# soc_aon_secure register map
Vendor: Texas Instruments
Registers are 32-bit, access per field, reset 0x0 unless marked. A register's access mark holds for its fields unless they carry their own. Offsets are as the file gives them; [hi:lo] are bit positions; {n}, {i} and the like mark numbered series; 'fields as' and 'values as' point back to an identical list; <NAME> marks a mode.

## soc_aon_secure (part 2 of 3)
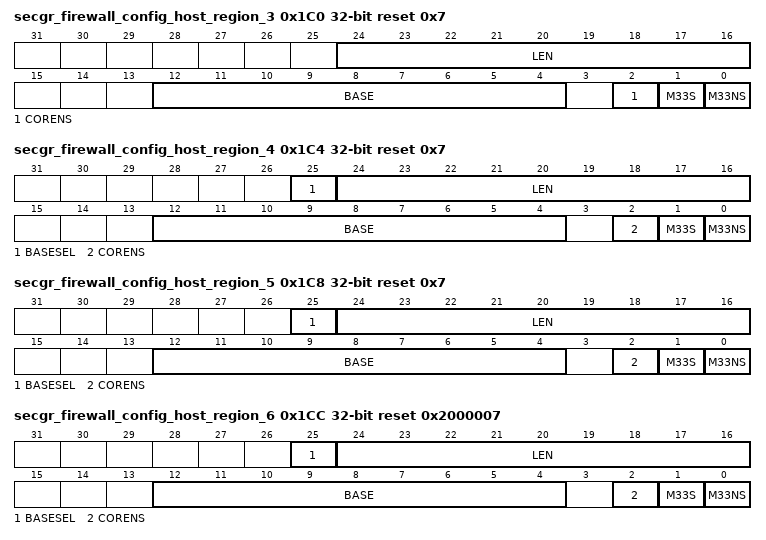
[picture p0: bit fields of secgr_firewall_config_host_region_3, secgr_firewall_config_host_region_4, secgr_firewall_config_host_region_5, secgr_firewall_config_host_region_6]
0x1C0 secgr_firewall_config_host_region_3 reset 0x7 — HOST MCU region 3 firewall access permission for 3 controller id : 0 - M33 Non Secured 1 - M33 Secured 2 - Core (Non Secure)
  [24:16] LEN rw — address base with 1K granularity : address base len for firewall is the offset from the region's base address indicated in the same region field describing the end of a firewall window that has a certain access rules (R/W Permission) for each controller-id HOST_MCU_REGION_0 address space: 0x20000000 - 0x2FFFFFFF HOST_MCU_REGION_0 base_len can range from: ##register base_len value## 0x0 - 0x7F for HOST_MCU_REGION_0 the base address for security firewalls is 0x20000000 ( HOST_MCU_REGION_0 ) max window size is 128Kb example: worker base address: 0x20000000 current address to access: 0x20001504 region_base_address: 0x4 region_base_address_len: 0x2 --> (region_base_address + region_base_address_len) --> 0x4+0x2 -->0x6 0x20001504 --> ((0x20001504 - 0x20000000) >> 10) -->0x4 0x4 <= 0x5 < 0x6 that address falls on the region window and therefor obeys to that region set of access rules
  [12:4] BASE rw — address base with 1K granularity : address base for firewall is the the offset start address from a worker base address describing the beginning of a firewall window that has a certain access rules (R/W Permission) for each controller-id HOST_MCU address space: 0x00000000 - 0x2FFFFFFF / 0x41900000 - 0x4190FFFF HOST_MCU_REGION_3 is assigned to TCM DATA RAM HOST_MCU_REGION_3 base address can range from: ##register base value## 0x0 - 0x1A0 ##absolute equivalent value## 0x280000000 - 0x280068000 for HOST_MCU_REGION_3 the base address for security firewalls is 0x280000000 ( M33 Data RAM ) max window size is 416Kb (depending on the MEMSS mode) example: worker base address: 0x280000000 current address to access: 0x28000504 region_base_address: 0x1 region_base_address_len: 0x1 0x28000504 --> ((0x28000504 - 0x280000000) >> 10) --> 0x1 0x1(base) <= 0x1(current) < 0x1(base)+0x1(len) that address falls on the region window and therefor obeys to that region set of access rules
  [2] CORENS rw — Controller Core Non Secured: '0' - access not allowed '1' - access allowed
  [1] M33S rw — Controller M33 Secured: '0' - access not allowed '1' - access allowed
  [0] M33NS rw — Controller M33 None Secured: '0' - access not allowed '1' - access allowed
0x1C4 secgr_firewall_config_host_region_4 reset 0x7 — access permission for 3 controller id : 0 - M33 Non Secured 1 - M33 Secured 2 - Core (Non Secure)
  [25] BASESEL rw — Base select for Reserved region defaulted to M33 TCM Data RAM (base_sel = 0): this select bit will assign this region to either TCM Data (base_sel = 0) ##register base value## 0x0 - 0x80 ##absolute equivalent value## 0x200000000 - 0x20001FFFF or Data RAM (base_sel = 1) ##register base value## 0x0 - 0x1A0 ##absolute equivalent value## 0x280000000 - 0x280067FFF for HOST_MCU_REGION_4 with base_sel = 0 the base address for security firewalls is 0x200000000 ( M33 TCM Data RAM ) max window size is 128Kb (depending on the MEMSS mode) for HOST_MCU_REGION_4 with base_sel = 1 the base address for security firewalls is 0x280000000 ( M33 Data RAM ) max window size is 416Kb (depending on the MEMSS mode) example: worker base address: 0x280000000 current address to access: 0x28000504 region_base_address: 0x1 region_base_address_len: 0x1 0x28000504 --> ((0x28000504 - 0x280000000) >> 10) --> 0x1 0x1(base) <= 0x1(current) < 0x1(base)+0x1(len) that address falls on the region window and therefor obeys to that region set of access rules
  [24:16] LEN rw — address base len for firewall is the offset from the region's base address indicated in the same region field describing the end of a firewall window that has a certain access rules (R/W Permission) for each controller-id HOST_MCU_REGION_4 address space: 0x20000000 - 0x2FFFFFFF HOST_MCU_REGION_4 base_len can range from: base_sel = 0 ##register base_len value## 0x0 - 0x7F base_sel = 0 --> HOST_MCU_REGION_4 the base address for security firewalls is 0x20000000 ( TCM M33 Data RAM ) max window size is 128Kb ################# base_sel = 1 ##register base_len value## 0x0 - 0x1A0 base_sel = 1 --> HOST_MCU_REGION_4 the base address for security firewalls is 0x28000000 (M33 Data RAM ) max window size is 416Kb ################# example: worker base address: 0x20000000 current address to access: 0x20001504 region_base_address: 0x4 region_base_address_len: 0x2 --> (region_base_address + region_base_address_len) --> 0x4+0x2 -->0x6 0x20001504 --> ((0x20001504 - 0x20000000) >> 10) -->0x4 0x4 <= 0x5 < 0x6 that address falls on the region window and therefor obeys to that region set of access rules
  [12:4] BASE rw — address base with 1K granularity : address base for firewall is the the offset start address from a worker base address describing the beginning of a firewall window that has a certain access rules (R/W Permission) for each controller-id HOST_MCU address space: 0x00000000 - 0x2FFFFFFF / 0x41900000 - 0x4190FFFF HOST_MCU_REGION_4 is assigned to TCM DATA RAM (base_sel = 0) or M33 Data Ram (base_sel = 1) HOST_MCU_REGION_4 base address can range from: (base_sel = 0) ##register base value## 0x0 - 0x80 ##absolute equivalent value## 0x200000000 - 0x20001FFFF for HOST_MCU_REGION_4 the base address for security firewalls is 0x200000000 ( TCM Data RAM ) max window size is 128Kb ################## (base_sel = 1) ##register base value## 0x0 - 0x1A0 ##absolute equivalent value## 0x280000000 - 0x280068000 for HOST_MCU_REGION_4 the base address for security firewalls is 0x280000000 ( M33 Data RAM ) max window size is 416Kb (depending on the MEMSS mode) example: worker base address: 0x280000000 current address to access: 0x28000504 region_base_address: 0x1 region_base_address_len: 0x1 0x28000504 --> ((0x28000504 - 0x280000000) >> 10) --> 0x1 0x1(base) <= 0x1(current) < 0x1(base)+0x1(len) that address falls on the region window and therefor obeys to that region set of access rules
  [2] CORENS rw — Controller Core Non Secured: '0' - access not allowed '1' - access allowed
  [1] M33S rw — Controller M33 Secured: '0' - access not allowed '1' - access allowed
  [0] M33NS rw — Controller M33 None Secured: '0' - access not allowed '1' - access allowed
0x1C8 secgr_firewall_config_host_region_5 reset 0x7 — HOST MCU region 5 firewall access permission for 3 controller id : 0 - M33 Non Secured 1 - M33 Secured 2 - Core (Non Secure)
  [25] BASESEL rw — Base select for Reserved region defaulted to M33 TCM Data RAM (base_sel = 0): this select bit will assign this region to either TCM Data (base_sel = 0) ##register base value## 0x0 - 0x80 ##absolute equivalent value## 0x200000000 - 0x20001FFFF or Data RAM (base_sel = 1) ##register base value## 0x0 - 0x1A0 ##absolute equivalent value## 0x280000000 - 0x280067FFF for HOST_MCU_REGION_5 with base_sel = 0 the base address for security firewalls is 0x200000000 ( M33 TCM Data RAM ) max window size is 128Kb (depending on the MEMSS mode) for HOST_MCU_REGION_5 with base_sel = 1 the base address for security firewalls is 0x280000000 ( M33 Data RAM ) max window size is 416Kb (depending on the MEMSS mode) example: worker base address: 0x280000000 current address to access: 0x28000504 region_base_address: 0x1 region_base_address_len: 0x1 0x28000504 --> ((0x28000504 - 0x280000000) >> 10) --> 0x1 0x1(base) <= 0x1(current) < 0x1(base)+0x1(len) that address falls on the region window and therefor obeys to that region set of access rules
  [24:16] LEN rw — address base len for firewall is the offset from the region's base address indicated in the same region field describing the end of a firewall window that has a certain access rules (R/W Permission) for each controller-id HOST_MCU_REGION_4 address space: 0x20000000 - 0x2FFFFFFF HOST_MCU_REGION_4 base_len can range from: base_sel = 0 ##register base_len value## 0x0 - 0x7F base_sel = 0 --> HOST_MCU_REGION_5 the base address for security firewalls is 0x20000000 ( TCM Data RAM ) max window size is 128Kb ################# base_sel = 1 ##register base_len value## 0x0 - 0x1A0 base_sel = 1 --> HOST_MCU_REGION_5 the base address for security firewalls is 0x28000000 ( M33 Data RAM ) max window size is 416Kb ################# example: worker base address: 0x20000000 current address to access: 0x20001504 region_base_address: 0x4 region_base_address_len: 0x2 --> (region_base_address + region_base_address_len) --> 0x4+0x2 -->0x6 0x20001504 --> ((0x20001504 - 0x20000000) >> 10) -->0x4 0x4 <= 0x5 < 0x6 that address falls on the region window and therefor obeys to that region set of access rules
  [12:4] BASE rw — address base with 1K granularity : address base for firewall is the the offset start address from a worker base address describing the beginning of a firewall window that has a certain access rules (R/W Permission) for each controller-id HOST_MCU address space: 0x00000000 - 0x2FFFFFFF / 0x41900000 - 0x4190FFFF HOST_MCU_REGION_5 is assigned to TCM DATA RAM (base_sel = 0) or M33 Data Ram (base_sel = 1) HOST_MCU_REGION_5 base address can range from: (base_sel = 0) ##register base value## 0x0 - 0x80 ##absolute equivalent value## 0x200000000 - 0x20001FFFF for HOST_MCU_REGION_5 the base address for security firewalls is 0x200000000 ( TCM Data RAM ) max window size is 128Kb ################## (base_sel = 1) ##register base value## 0x0 - 0x1A0 ##absolute equivalent value## 0x280000000 - 0x280068000 for HOST_MCU_REGION_5 the base address for security firewalls is 0x280000000 ( M33 Data RAM ) max window size is 416Kb (depending on the MEMSS mode) example: worker base address: 0x280000000 current address to access: 0x28000504 region_base_address: 0x1 region_base_address_len: 0x1 0x28000504 --> ((0x28000504 - 0x280000000) >> 10) --> 0x1 0x1(base) <= 0x1(current) < 0x1(base)+0x1(len) that address falls on the region window and therefor obeys to that region set of access rules
  [2] CORENS rw — Controller Core Non Secured: '0' - access not allowed '1' - access allowed
  [1] M33S rw — Controller M33 Secured: '0' - access not allowed '1' - access allowed
  [0] M33NS rw — Controller M33 None Secured: '0' - access not allowed '1' - access allowed
0x1CC secgr_firewall_config_host_region_6 reset 0x2000007 — HOST MCU region 6 firewall access permission for 3 controller id : 0 - M33 Non Secured 1 - M33 Secured 2 - Core (Non Secure)
  [25] BASESEL rw — Base select for Reserved region defaulted to M33 Data RAM (base_sel = 1): this select bit will assign this region to either TCM Data (base_sel = 0) ##register base value## 0x0 - 0x80 ##absolute equivalent value## 0x200000000 - 0x20001FFFF or Data RAM (base_sel = 1) ##register base value## 0x0 - 0x1A0 ##absolute equivalent value## 0x280000000 - 0x280067FFF for HOST_MCU_REGION_4 with base_sel = 0 the base address for security firewalls is 0x200000000 ( M33 TCM Data RAM ) max window size is 128Kb (depending on the MEMSS mode) for HOST_MCU_REGION_4 with base_sel = 1 the base address for security firewalls is 0x280000000 ( M33 Data RAM ) max window size is 416Kb (depending on the MEMSS mode) example: worker base address: 0x280000000 current address to access: 0x28000504 region_base_address: 0x1 region_base_address_len: 0x1 0x28000504 --> ((0x28000504 - 0x280000000) >> 10) --> 0x1 0x1(base) <= 0x1(current) < 0x1(base)+0x1(len) that address falls on the region window and therefor obeys to that region set of access rules
  [24:16] LEN rw — address base len for firewall is the offset from the region's base address indicated in the same region field describing the end of a firewall window that has a certain access rules (R/W Permission) for each controller-id HOST_MCU_REGION_6 address space: 0x20000000 - 0x2FFFFFFF HOST_MCU_REGION_6 base_len can range from: base_sel = 0 ##register base_len value## 0x0 - 0x7F base_sel = 0 --> HOST_MCU_REGION_6 the base address for security firewalls is 0x20000000 ( TCM Data RAM) max window size is 128Kb ################# base_sel = 1 ##register base_len value## 0x0 - 0x1A0 base_sel = 1 --> HOST_MCU_REGION_6 the base address for security firewalls is 0x28000000 ( M33 Data RAM ) max window size is 416Kb ################# example: worker base address: 0x20000000 current address to access: 0x20001504 region_base_address: 0x4 region_base_address_len: 0x2 --> (region_base_address + region_base_address_len) --> 0x4+0x2 -->0x6 0x20001504 --> ((0x20001504 - 0x20000000) >> 10) -->0x4 0x4 <= 0x5 < 0x6 that address falls on the region window and therefor obeys to that region set of access rules
  [12:4] BASE rw — address base with 1K granularity : address base for firewall is the the offset start address from a worker base address describing the beginning of a firewall window that has a certain access rules (R/W Permission) for each controller-id HOST_MCU address space: 0x00000000 - 0x2FFFFFFF / 0x41900000 - 0x4190FFFF HOST_MCU_REGION_6 is assigned to TCM DATA RAM (base_sel = 0) or M33 Data Ram (base_sel = 1) HOST_MCU_REGION_6 base address can range from: (base_sel = 0) ##register base value## 0x0 - 0x80 ##absolute equivalent value## 0x200000000 - 0x20001FFFF for HOST_MCU_REGION_6 the base address for security firewalls is 0x200000000 ( TCM Data RAM ) max window size is 128Kb ################## (base_sel = 1) ##register base value## 0x0 - 0x1A0 ##absolute equivalent value## 0x280000000 - 0x280068000 for HOST_MCU_REGION_6 the base address for security firewalls is 0x280000000 ( M33 Data RAM ) max window size is 416Kb (depending on the MEMSS mode) example: worker base address: 0x280000000 current address to access: 0x28000504 region_base_address: 0x1 region_base_address_len: 0x1 0x28000504 --> ((0x28000504 - 0x280000000) >> 10) --> 0x1 0x1(base) <= 0x1(current) < 0x1(base)+0x1(len) that address falls on the region window and therefor obeys to that region set of access rules
  [2] CORENS rw — Controller Core Non Secured: '0' - access not allowed '1' - access allowed
  [1] M33S rw — Controller M33 Secured: '0' - access not allowed '1' - access allowed
  [0] M33NS rw — Controller M33 None Secured: '0' - access not allowed '1' - access allowed
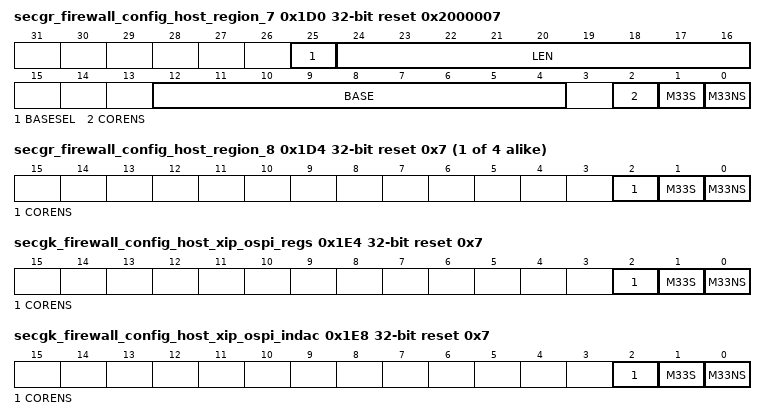
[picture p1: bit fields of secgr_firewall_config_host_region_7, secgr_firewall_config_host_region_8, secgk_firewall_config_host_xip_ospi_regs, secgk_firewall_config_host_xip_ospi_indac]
0x1D0 secgr_firewall_config_host_region_7 reset 0x2000007 — HOST MCU region 7 firewall access permission for 3 controller id : 0 - M33 Non Secured 1 - M33 Secured 2 - Core (Non Secure)
  [25] BASESEL rw — Base select for Reserved region defaulted to M33 Data RAM (base_sel = 1) : this select bit will assign this region to either TCM Data (base_sel = 0) ##register base value## 0x0 - 0x80 ##absolute equivalent value## 0x200000000 - 0x20001FFFF or Data RAM (base_sel = 1) ##register base value## 0x0 - 0x1A0 ##absolute equivalent value## 0x280000000 - 0x280067FFF for HOST_MCU_REGION_4 with base_sel = 0 the base address for security firewalls is 0x200000000 ( M33 TCM Data RAM ) max window size is 128Kb (depending on the MEMSS mode) for HOST_MCU_REGION_4 with base_sel = 1 the base address for security firewalls is 0x280000000 ( M33 Data RAM ) max window size is 416Kb (depending on the MEMSS mode) example: worker base address: 0x280000000 current address to access: 0x28000504 region_base_address: 0x1 region_base_address_len: 0x1 0x28000504 --> ((0x28000504 - 0x280000000) >> 10) --> 0x1 0x1(base) <= 0x1(current) < 0x1(base)+0x1(len) that address falls on the region window and therefor obeys to that region set of access rules
  [24:16] LEN rw — address base len for firewall is the offset from the region's base address indicated in the same region field describing the end of a firewall window that has a certain access rules (R/W Permission) for each controller-id HOST_MCU_REGION_7 address space: 0x20000000 - 0x2FFFFFFF HOST_MCU_REGION_7 base_len can range from: base_sel = 0 ##register base_len value## 0x0 - 0x7F base_sel = 0 --> HOST_MCU_REGION_7 the base address for security firewalls is 0x20000000 (TCM Data RAM) max window size is 128Kb ################# base_sel = 1 ##register base_len value## 0x0 - 0x1A0 base_sel = 1 --> HOST_MCU_REGION_7 the base address for security firewalls is 0x28000000 (M33 Data RAM) max window size is 416Kb ################# example: worker base address: 0x20000000 current address to access: 0x20001504 region_base_address: 0x4 region_base_address_len: 0x2 --> (region_base_address + region_base_address_len) --> 0x4+0x2 -->0x6 0x20001504 --> ((0x20001504 - 0x20000000) >> 10) -->0x4 0x4 <= 0x5 < 0x6 that address falls on the region window and therefor obeys to that region set of access rules
  [12:4] BASE rw — address base with 1K granularity : address base for firewall is the the offset start address from a worker base address describing the beginning of a firewall window that has a certain access rules (R/W Permission) for each controller-id HOST_MCU address space: 0x00000000 - 0x2FFFFFFF / 0x41900000 - 0x4190FFFF HOST_MCU_REGION_7 is assigned to TCM DATA RAM (base_sel = 0) or M33 Data Ram (base_sel = 1) HOST_MCU_REGION_7 base address can range from: (base_sel = 0) ##register base value## 0x0 - 0x80 ##absolute equivalent value## 0x200000000 - 0x20001FFFF for HOST_MCU_REGION_7 the base address for security firewalls is 0x200000000 ( TCM Data RAM ) max window size is 128Kb ################## (base_sel = 1) ##register base value## 0x0 - 0x1A0 ##absolute equivalent value## 0x280000000 - 0x280068000 for HOST_MCU_REGION_7 the base address for security firewalls is 0x280000000 ( M33 Data RAM ) max window size is 416Kb (depending on the MEMSS mode) example: worker base address: 0x280000000 current address to access: 0x28000504 region_base_address: 0x1 region_base_address_len: 0x1 0x28000504 --> ((0x28000504 - 0x280000000) >> 10) --> 0x1 0x1(base) <= 0x1(current) < 0x1(base)+0x1(len) that address falls on the region window and therefor obeys to that region set of access rules
  [2] CORENS rw — Controller Core Non Secured: '0' - access not allowed '1' - access allowed
  [1] M33S rw — Controller M33 Secured: '0' - access not allowed '1' - access allowed
  [0] M33NS rw — Controller M33 None Secured: '0' - access not allowed '1' - access allowed
{0x1B4+4i} secgr_firewall_config_host_region_{i} reset 0x7 (i=8..11) — HOST MCU region {i} firewall access permission for 3 controller id : 0 - M33 Non Secured 1 - M33 Secured 2 - Core (Non Secure)
  [2] CORENS rw — Controller Core Non Secured: '0' - access not allowed '1' - access allowed
  [1] M33S rw — Controller M33 Secured: '0' - access not allowed '1' - access allowed
  [0] M33NS rw — Controller M33 None Secured: '0' - access not allowed '1' - access allowed
0x1E4 secgk_firewall_config_host_xip_ospi_regs reset 0x7 — XIP_OSPI firewall access permission for 3 controller id : 0 - M33 Non Secured 1 - M33 Secured 2 - Core (Non Secure)
  fields as secgr_firewall_config_host_region_8
0x1E8 secgk_firewall_config_host_xip_ospi_indac reset 0x7 — OSPI_INDAC firewall access permission for 3 controller id : 0 - M33 Non Secured 1 - M33 Secured 2 - Core (Non Secure)
  fields as secgr_firewall_config_host_region_8
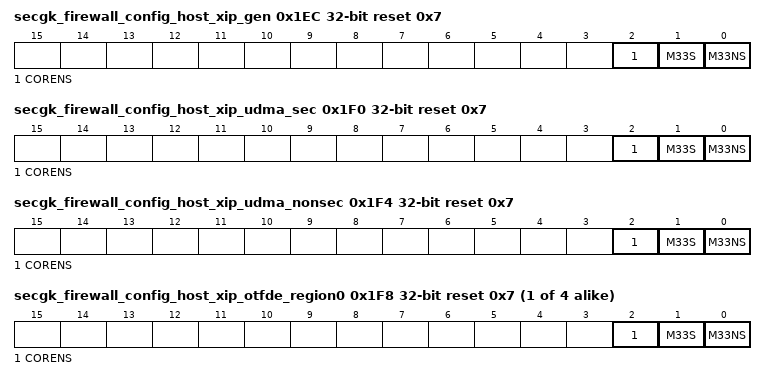
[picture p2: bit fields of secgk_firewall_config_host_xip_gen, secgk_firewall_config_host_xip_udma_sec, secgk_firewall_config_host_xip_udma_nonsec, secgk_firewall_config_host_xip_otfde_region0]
0x1EC secgk_firewall_config_host_xip_gen reset 0x7 — XIP_GEN firewall access permission for 3 controller id : 0 - M33 Non Secured 1 - M33 Secured 2 - Core (Non Secure)
  fields as secgr_firewall_config_host_region_8
0x1F0 secgk_firewall_config_host_xip_udma_sec reset 0x7 — XIP_UDMA_SEC firewall access permission for 3 controller id : 0 - M33 Non Secured 1 - M33 Secured 2 - Core (Non Secure)
  fields as secgr_firewall_config_host_region_8
0x1F4 secgk_firewall_config_host_xip_udma_nonsec reset 0x7 — UDMA_NONSEC firewall access permission for 3 controller id : 0 - M33 Non Secured 1 - M33 Secured 2 - Core (Non Secure)
  fields as secgr_firewall_config_host_region_8
{0x1F8+4i} secgk_firewall_config_host_xip_otfde_region{i} reset 0x7 (i=0..3) — OTFDE_REGION{i} firewall access permission for 3 controller id : 0 - M33 Non Secured 1 - M33 Secured 2 - Core (Non Secure)
  fields as secgr_firewall_config_host_region_8
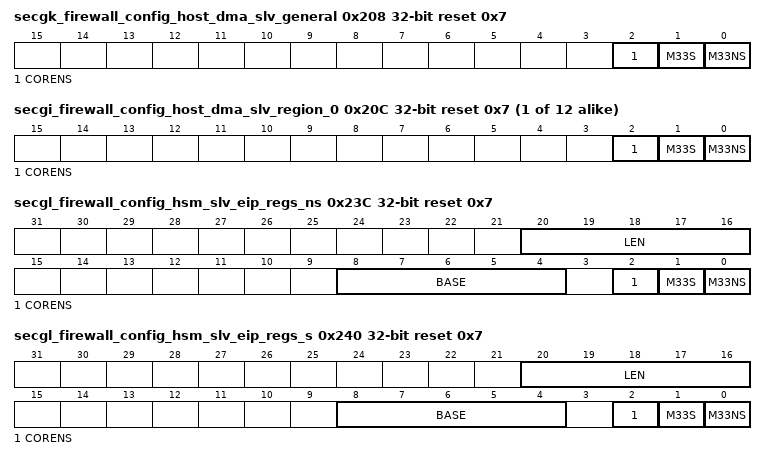
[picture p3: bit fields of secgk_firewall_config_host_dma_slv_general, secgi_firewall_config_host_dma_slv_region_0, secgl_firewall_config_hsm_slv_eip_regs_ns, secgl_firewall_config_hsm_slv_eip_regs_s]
0x208 secgk_firewall_config_host_dma_slv_general reset 0x7 — DMA_GEN firewall access permission for 3 controller id : 0 - M33 Non Secured 1 - M33 Secured 2 - Core (Non Secure)
  fields as secgr_firewall_config_host_region_8
{0x20C+4i} secgi_firewall_config_host_dma_slv_region_{i} reset 0x7 (i=0..11) — DMA_CH_{i} firewall access permission for 3 controller id : 0 - M33 Non Secured 1 - M33 Secured 2 - Core (Non Secure)
  fields as secgr_firewall_config_host_region_8
0x23C secgl_firewall_config_hsm_slv_eip_regs_ns reset 0x7 — HSM EIP NONSEC firewall access permission for 3 controller id : 0 - M33 Non Secured 1 - M33 Secured 2 - Core (Non Secure)
  [20:16] LEN rw — address base with 1K granularity : address base len for firewall is the offset from the region's base address indicated in the same region field describing the end of a firewall window that has a certain access rules (R/W Permission) for each controller-id HSM address space: 0x41B00000 - 0x41B3FFFF HSM_EIP_REGS base_len can range from: ##register base_len value## 0x0 - 0xF for HSM the base address for security firewalls is 0x41B00000 ( HSM_EIP_REGS ) max window size is 16Kb example: worker base address: 0x41B00000 current address to access: 0x41B01504 region_base_address: 0x4 region_base_address_len: 0x2 --> (region_base_address + region_base_address_len) --> 0x4+0x2 -->0x6 0x41B01504 --> ((0x41B01504 - 0x41B00000) >> 10) -->0x4 0x4 <= 0x5 < 0x6 that address falls on the region window and therefor obeys to that region set of access rules
  [8:4] BASE rw — address base with 1K granularity : address base for firewall is the the offset start address from a worker base address describing the beginning of a firewall window that has a certain access rules (R/W Permission) for each controller-id HSM address space: 0x41B00000 - 0x41B3FFFF HSM_EIP_REGS base address can range from: ##register base value## 0x0 - 0xF ##absolute equivalent value## 0x41B00000 - 0x41B03FFF for HSM the base address for security firewalls is 0x41B00000 ( HSM_EIP_REGS ) max window size is 16Kb example: worker base address: 0x41B00000 current address to access: 0x41B00504 region_base_address: 0x1 region_base_address_len: 0x1 0x41B00504 --> ((0x41B00504 - 0x41B00000) >> 10) --> 0x1 0x1(base) <= 0x1(current) < 0x1(base)+0x1(len) that address falls on the region window and therefor obeys to that region set of access rules
  [2] CORENS rw — Controller Core Non Secured: '0' - access not allowed '1' - access allowed
  [1] M33S rw — Controller M33 Secured: '0' - access not allowed '1' - access allowed
  [0] M33NS rw — Controller M33 None Secured: '0' - access not allowed '1' - access allowed
0x240 secgl_firewall_config_hsm_slv_eip_regs_s reset 0x7 — HSM EIP SEC firewall access permission for 3 controller id : 0 - M33 Non Secured 1 - M33 Secured 2 - Core (Non Secure)
  [20:16] LEN rw — address base with 1K granularity : address base len for firewall is the offset from the region's base address indicated in the same region field describing the end of a firewall window that has a certain access rules (R/W Permission) for each controller-id HSM address space: 0x41B00000 - 0x41B3FFFF HSM_EIP_REGS base_len can range from: ##register base_len value## 0x0 - 0xF for HSM the base address for security firewalls is 0x41B00000 ( HSM_EIP_REGS ) max window size is 16Kb example: worker base address: 0x41B00000 current address to access: 0x41B01504 region_base_address: 0x4 region_base_address_len: 0x2 --> (region_base_address + region_base_address_len) --> 0x4+0x2 -->0x6 0x41B01504 --> ((0x41B01504 - 0x41B00000) >> 10) -->0x4 0x4 <= 0x5 < 0x6 that address falls on the region window and therefor obeys to that region set of access rules
  [8:4] BASE rw — address base with 1K granularity : address base for firewall is the the offset start address from a worker base address describing the beginning of a firewall window that has a certain access rules (R/W Permission) for each controller-id HSM address space: 0x41B00000 - 0x41B3FFFF HSM_EIP_REGS base address can range from: ##register base value## 0x0 - ##absolute equivalent value## 0x41B00000 - 0x41B03FFF for HSM the base address for security firewalls is 0x41B00000 ( HSM_EIP_REGS ) max window size is 16Kb example: worker base address: 0x41B00000 current address to access: 0x41B00504 region_base_address: 0x1 region_base_address_len: 0x1 0x41B00504 --> ((0x41B00504 - 0x41B00000) >> 10) --> 0x1 0x1(base) <= 0x1(current) < 0x1(base)+0x1(len) that address falls on the region window and therefor obeys to that region set of access rules
  [2] CORENS rw — Controller Core Non Secured: '0' - access not allowed '1' - access allowed
  [1] M33S rw — Controller M33 Secured: '0' - access not allowed '1' - access allowed
  [0] M33NS rw — Controller M33 None Secured: '0' - access not allowed '1' - access allowed
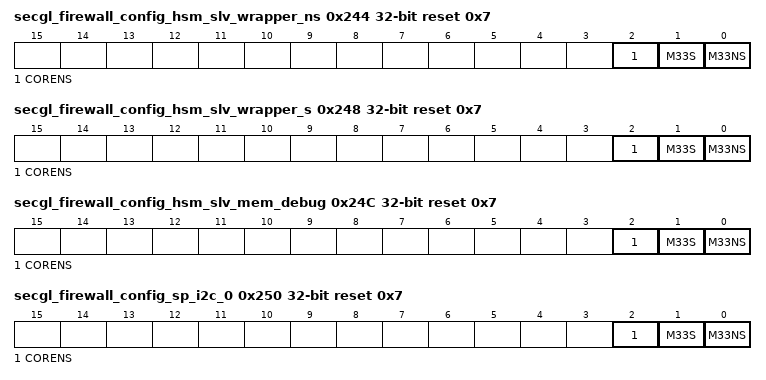
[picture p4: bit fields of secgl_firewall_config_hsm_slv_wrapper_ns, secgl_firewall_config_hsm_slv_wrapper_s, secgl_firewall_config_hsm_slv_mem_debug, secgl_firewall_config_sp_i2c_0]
0x244 secgl_firewall_config_hsm_slv_wrapper_ns reset 0x7 — HSM Wrapper NONSEC firewall access permission for 3 controller id : 0 - M33 Non Secured 1 - M33 Secured 2 - Core (Non Secure)
  fields as secgr_firewall_config_host_region_8
0x248 secgl_firewall_config_hsm_slv_wrapper_s reset 0x7 — HSM Wrapper SEC firewall access permission for 3 controller id : 0 - M33 Non Secured 1 - M33 Secured 2 - Core (Non Secure)
  fields as secgr_firewall_config_host_region_8
0x24C secgl_firewall_config_hsm_slv_mem_debug reset 0x7 — HSM DEBUG firewall access permission for 3 controller id : 0 - M33 Non Secured 1 - M33 Secured 2 - Core (Non Secure)
  fields as secgr_firewall_config_host_region_8
0x250 secgl_firewall_config_sp_i2c_0 reset 0x7 — I2C0 firewall access permission for 3 controller id : 0 - M33 Non Secured 1 - M33 Secured 2 - Core (Non Secure)
  fields as secgr_firewall_config_host_region_8
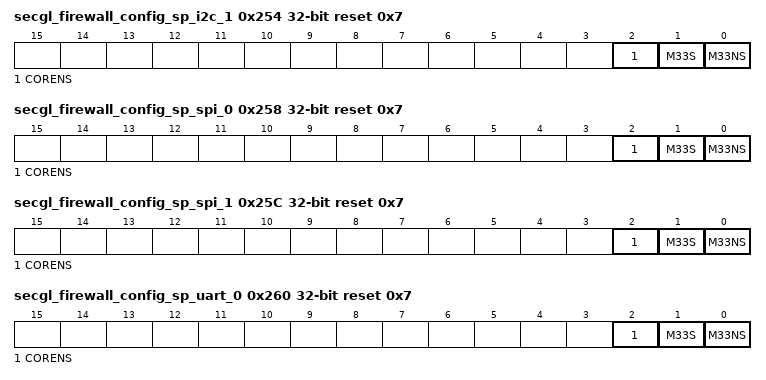
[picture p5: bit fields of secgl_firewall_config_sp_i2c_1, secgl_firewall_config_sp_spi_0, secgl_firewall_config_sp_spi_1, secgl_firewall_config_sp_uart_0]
0x254 secgl_firewall_config_sp_i2c_1 reset 0x7 — I2C1 firewall access permission for 3 controller id : 0 - M33 Non Secured 1 - M33 Secured 2 - Core (Non Secure)
  fields as secgr_firewall_config_host_region_8
0x258 secgl_firewall_config_sp_spi_0 reset 0x7 — SPI0 firewall access permission for 3 controller id : 0 - M33 Non Secured 1 - M33 Secured 2 - Core (Non Secure)
  fields as secgr_firewall_config_host_region_8
0x25C secgl_firewall_config_sp_spi_1 reset 0x7 — SPI1 firewall access permission for 3 controller id : 0 - M33 Non Secured 1 - M33 Secured 2 - Core (Non Secure)
  fields as secgr_firewall_config_host_region_8
0x260 secgl_firewall_config_sp_uart_0 reset 0x7 — UART0 firewall access permission for 3 controller id : 0 - M33 Non Secured 1 - M33 Secured 2 - Core (Non Secure)
  fields as secgr_firewall_config_host_region_8
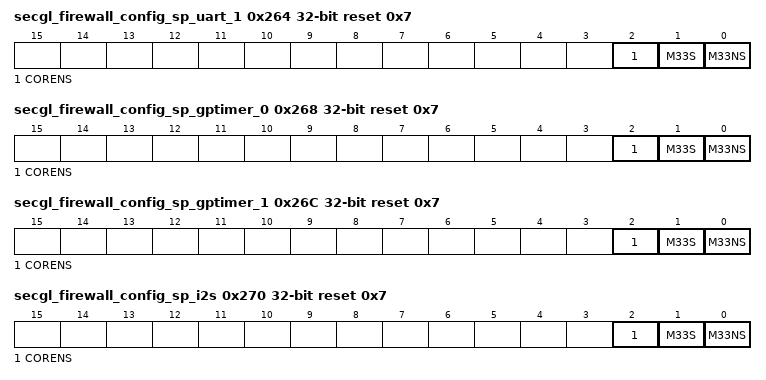
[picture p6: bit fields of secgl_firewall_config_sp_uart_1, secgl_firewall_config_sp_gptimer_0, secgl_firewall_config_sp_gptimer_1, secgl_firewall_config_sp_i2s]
0x264 secgl_firewall_config_sp_uart_1 reset 0x7 — UART1 firewall access permission for 3 controller id : 0 - M33 Non Secured 1 - M33 Secured 2 - Core (Non Secure)
  fields as secgr_firewall_config_host_region_8
0x268 secgl_firewall_config_sp_gptimer_0 reset 0x7 — GPTIMER0 firewall access permission for 3 controller id : 0 - M33 Non Secured 1 - M33 Secured 2 - Core (Non Secure)
  fields as secgr_firewall_config_host_region_8
0x26C secgl_firewall_config_sp_gptimer_1 reset 0x7 — GPTIMER1 firewall access permission for 3 controller id : 0 - M33 Non Secured 1 - M33 Secured 2 - Core (Non Secure)
  fields as secgr_firewall_config_host_region_8
0x270 secgl_firewall_config_sp_i2s reset 0x7 — I2S firewall access permission for 3 controller id : 0 - M33 Non Secured 1 - M33 Secured 2 - Core (Non Secure)
  fields as secgr_firewall_config_host_region_8
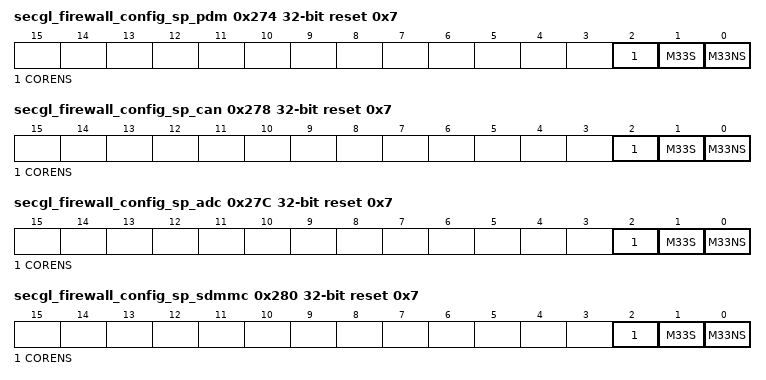
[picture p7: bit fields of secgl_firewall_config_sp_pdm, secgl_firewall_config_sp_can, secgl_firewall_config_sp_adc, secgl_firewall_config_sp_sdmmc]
0x274 secgl_firewall_config_sp_pdm reset 0x7 — PDM firewall access permission for 3 controller id : 0 - M33 Non Secured 1 - M33 Secured 2 - Core (Non Secure)
  fields as secgr_firewall_config_host_region_8
0x278 secgl_firewall_config_sp_can reset 0x7 — CAN firewall access permission for 3 controller id : 0 - M33 Non Secured 1 - M33 Secured 2 - Core (Non Secure)
  fields as secgr_firewall_config_host_region_8
0x27C secgl_firewall_config_sp_adc reset 0x7 — ADC firewall access permission for 3 controller id : 0 - M33 Non Secured 1 - M33 Secured 2 - Core (Non Secure)
  fields as secgr_firewall_config_host_region_8
0x280 secgl_firewall_config_sp_sdmmc reset 0x7 — SDMMC firewall access permission for 3 controller id : 0 - M33 Non Secured 1 - M33 Secured 2 - Core (Non Secure)
  fields as secgr_firewall_config_host_region_8
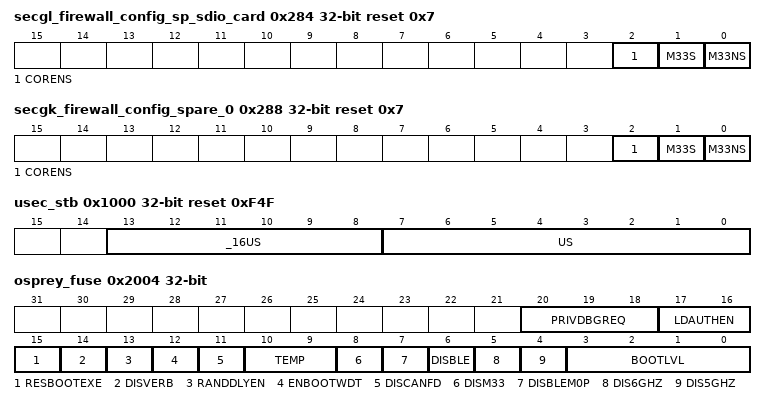
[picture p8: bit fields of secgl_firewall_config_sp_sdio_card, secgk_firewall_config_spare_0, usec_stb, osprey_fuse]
0x284 secgl_firewall_config_sp_sdio_card reset 0x7 — SDIO firewall access permission for 3 controller id : 0 - M33 Non Secured 1 - M33 Secured 2 - Core (Non Secure)
  fields as secgr_firewall_config_host_region_8
0x288 secgk_firewall_config_spare_0 reset 0x7 — Spare firewall access register. locked by HOST BOOT DONE (secgk) 3 access bits - {M33NS , M33S , M3} .
  fields as secgr_firewall_config_host_region_8
0x1000 usec_stb reset 0xF4F — Micro Second STB
  [13:8] _16US rw — Set how many micro second strobes are in 16 micro seconds, minus 1. Default: 16-1 =15.
  [7:0] US rw — Set how many soc clk are in one micro second, minus 1. for 40mhz : should be 39. for 80mhz : should be 79. (Soc clock default is 80MHz)
0x1004 doorbell2_m2_clr — Doorbell 2 M33 Clear Register
  [0] CLR wo — M33 to clear the IRQ when handled the massage from M3 Type: Write-Clear
0x1008 doorbell2_m2_pulse — Doorbell 2 M33 Set Register
  [0] SET wo — M33 to generate IRQ towards M3 after writing the message Type: Write-Clear
0x100C doorbell2_m2_lockbit — Doorbell 2 M33 Lockbit Register
  [1:0] LOCKBIT rw — Lock Bit. S/w attempt to lock upon read. if lock obtained, value set to 2 by h/w. M33 always looses to M3 Reading value: 00: not taken 01: taken by M3 10: taken by M33 (should wr IRQ afterwards) 11: invalid. generating the IRQ towards M1 clears the lock. Writing '00' also release the lock. 2'b01 means lock obtained by receiver side Type: Write-Read-Clear
0x1010 doorbell3_m2_clr — Doorbell 3 M33 Clear Register
  fields as doorbell2_m2_clr
0x1014 doorbell3_m2_pulse — Doorbell 3 M33 Set Register
  fields as doorbell2_m2_pulse
0x1018 doorbell3_m2_lockbit — Doorbell 3 M33 Lockbit Register
  fields as doorbell2_m2_lockbit
0x101C doorbell6_m2_clr — Doorbell 6 M33 Clear Register
  fields as doorbell2_m2_clr
0x1020 doorbell6_m2_pulse — Doorbell 6 M33 Set Register
  fields as doorbell2_m2_pulse
0x1024 doorbell6_m2_lockbit — Doorbell 6 M33 Lockbit Register
  fields as doorbell2_m2_lockbit
0x1028 doorbell7_m2_clr — Doorbell 7 M33 Clear Register
  fields as doorbell2_m2_clr
0x102C doorbell7_m2_pulse — Doorbell 7 M33 Set Register
  fields as doorbell2_m2_pulse
0x1030 doorbell7_m2_lockbit — Doorbell 7 M33 Lockbit Register
  fields as doorbell2_m2_lockbit
0x1044 non_secured_gpio_evt_sts_0 ro — Non-Secured GPIO Event Status, 1st Register. 45 bits status over two registers.
  [31:0] STA31TO0 — Non-Secured event status , first 32 bits. ([31:0])
0x1048 non_secured_gpio_evt_sts_1 ro — Non-Secured GPIO Event Status, 2nd Register. 45 bits status over two registers.
  [12:0] STA44TO32 — Non-Secured event status , 13 MSBs. ([44:32])
0x1054 db_m33_non_sec_imask reset 0xFFFF0 (reset mask 0xFFFFFFF0) — M33 Non-Secured Doorbell IMASK. Mask Event. '0' - CLR - Clear Interrupt Mask '1' - SET - Set Interrupt Mask
  [3:0] IMASK rw — bit3 - doorbell 7 M3 IRQ bit2 - doorbell 6 M3 IRQ bit1 - doorbell 3 M3 IRQ bit0 - doorbell 2 M3 IRQ
0x1058 db_m33_non_sec_iset_evt_mng — M33 Non-Secured Doorbells ISET. Sets event in RIS Write 0 - NO_EFFECT - Writing 0 has no effect Write 1 - SET - Sets interrupt
  [3:0] ISET wo — bit3 - doorbell 7 M3 IRQ bit2 - doorbell 6 M3 IRQ bit1 - doorbell 3 M3 IRQ bit0 - doorbell 2 M3 IRQ Type: Write-Clear
0x105C db_m33_non_sec_iclr_evt_mng — M33 Non-Secured Doorbell ICLR. Clears event in RIS Write 0 - NO_EFFECT - Writing 0 has no effect Write 1 - CLR - Clears the Event
  [3:0] ICLR wo — bit3 - doorbell 7 M3 IRQ bit2 - doorbell 6 M3 IRQ bit1 - doorbell 3 M3 IRQ bit0 - doorbell 2 M3 IRQ Type: Write-Clear
0x1060 db_m33_non_sec_imset_evt_mng — M33 Non-Secured Doorbell IMSET. Sets Event Write 0 - NO_EFFECT - Writing 0 has no effect Write 1 - SET - Set interrupt mask
  [3:0] IMSET wo — bit3 - doorbell 7 M3 IRQ bit2 - doorbell 6 M3 IRQ bit1 - doorbell 3 M3 IRQ bit0 - doorbell 2 M3 IRQ Type: Write-Clear
0x1064 db_m33_non_sec_imclr_evt_mng — M33 Non-Secured Doorbell IMCLR, Clears Event Write 0 - NO_EFFECT - Writing 0 has no effect Write 1 - CLR - Clear interrupt mask
  [3:0] IMCLR wo — bit3 - doorbell 7 M3 IRQ bit2 - doorbell 6 M3 IRQ bit1 - doorbell 3 M3 IRQ bit0 - doorbell 2 M3 IRQ Type: Write-Clear
0x1068 db_m33_non_sec_ris_evt_mng ro — M33 Non-Secured Doorbell RIS. Raw interrupt status for event. This bit is set to 1 when an event is received. when the corresponding bit in ICLR is set to 1, this bit will be cleared. Read 0 - CLR - Interrupt did not occur Read 1 - SET - Interrupt occurred
  [3:0] RIS — bit3 - doorbell 7 M3 IRQ bit2 - doorbell 6 M3 IRQ bit1 - doorbell 3 M3 IRQ bit0 - doorbell 2 M3 IRQ
0x106C db_m33_non_sec_mis_evt_mng ro — M33 Non-Secured Doorbell MIS. Mask interrupt status for event Read 0 - CLR - Interrupt did not occur Read 1 - SET - Interrupt occurred
  [3:0] MIS — bit3 - doorbell 7 M3 IRQ bit2 - doorbell 6 M3 IRQ bit1 - doorbell 3 M3 IRQ bit0 - doorbell 2 M3 IRQ
0x1070 non_secured_gpio_mis_0 ro — Non Secured GPIO MIS. 31-0
  [31:0] _31TO0 — 32 LSBs of GPIO MIS
0x1074 non_secured_gpio_mis_1 ro — Non Secure GPIO MIS. 44-32
  [12:0] _44TO32 — 13 MSBs of GPIO MIS. 44-32
0x1078 non_secured_gpio_func_0 rw — Non Secured GPIO Functional Mask. 31-0 0. Mask 1. Un-Mask
  [31:0] MASK31TO0 — 32 LSBs of non-secured functional mask for GPIO.
0x107C non_secured_gpio_func_1 — non secured gpio functional mask
  [12:0] MASK44TO32 rw — 13 MSBs of non-secured functional mask for GPIO. 44-32
0x1080 m33ns_spare — Spare Register for M22 Secured Aperture. not locked.
  [3:0] BF rw — M33NS spare register. not locked.
0x2004 osprey_fuse ro — Selected Security Fuse Lines. This register contain selected fields reflects Security from Fuse lines.
  [20:18] PRIVDBGREQ — Enforce TI privilege Debug Request (Relevant in AT TEST privilege only used by SW) 0 - Disable other (1-7) - Enable (When SW check these bits: if equal to '0' bypass otherwise check.)
  [17:16] LDAUTHEN — RAM Bootloader authentication enable: 00 - Disable Other- Enable
  [15] RESBOOTEXE — Resume boot in non-normal boot flows where the boot cannot progress (e.g. when assets are hidden). For example, in forced supply in operational or deployed life cycles, 1st bday/at test (normal) life cycles, etc. 0 - Halt boot execution as early as possible 1 - Resume/Continue boot execution This bit is ignored when the device can run the boot flow normally (e.g. deployed life cycle with default SOP).
  [14] DISVERB — Disable Verbose Mode 0 - Verbose Mode (Enable) - Full Logger 1 - Normal Mode (Disable)
  [13] RANDDLYEN — Random Delay Enable: 0 - Disable 1 - Enable
  [12] ENBOOTWDT — Enable watchdog timer for protecting boot: (This enable M33 watchdog second threshold to reset device when asserted). 0 - Disable Boot Watchdog 1 - Enable Boot Watchdog
  [11] DISCANFD — Disable CAN FD - to eliminate the need to pay royalties 0 - Enable 1 - Disable (In probe we can program '0' (which practically means not programming) to achieve continuous programming it of all shifted rows) HCANEN (Enable/Disable the CAN IP) - Determined according to paper spin HCANRAMEN(Enable disable access to CAN memory) - Determined according to paper spin. HCANFDEN - Disable/Enable CAN. Determined according to eFuse bit (this bit)
  [10:9] TEMP — Supported Temperature 00 - 85degC 01 - 105degC 10 - 125degC 11 - Reserved
  [8] DISM33 — Disable M33 0 - Enable 1 - Disable (In probe we can program '0' (which practically means not programming) to achieve continuous programming it of all shifted rows)
  [7] DISBLEM0P — Disable BLE M0+ (RFC_CPE_CLKEN ) 0 - Enable 1 - Disable (In probe we can program '0' (which practically means not programming) to achieve continuous programming it of all shifted rows)
  [6] DISBLE — Disable BLE (RFC_MDM_CLKEN) 0 - Enable 1 - Disable (In probe we can program '0' (which practically means not programming) to achieve continuous programming it of all shifted rows)
  [5] DIS6GHZ — Disable 6GHz 0 - Enable 1 - Disable (In probe we can program '0' (which practically means not programming) to achieve continuous programming it of all shifted rows)
  [4] DIS5GHZ — Disable 5GHz 0 - Enable 1 - Disable (In probe we can program '0' (which practically means not programming) to achieve continuous programming it of all shifted rows)
  [3:0] BOOTLVL — Determine which part of the boot ROM bypass options for risk mitigation Level0 - Do not bypass anything Level1- Ignore Error Level2 - TI ROM bypass Level3 - Minimize access to HW. Do min mandatory. 0b0110 - Level3 0b1010 - Level 2 0b0101 - Level 1 All the rest - Level 0
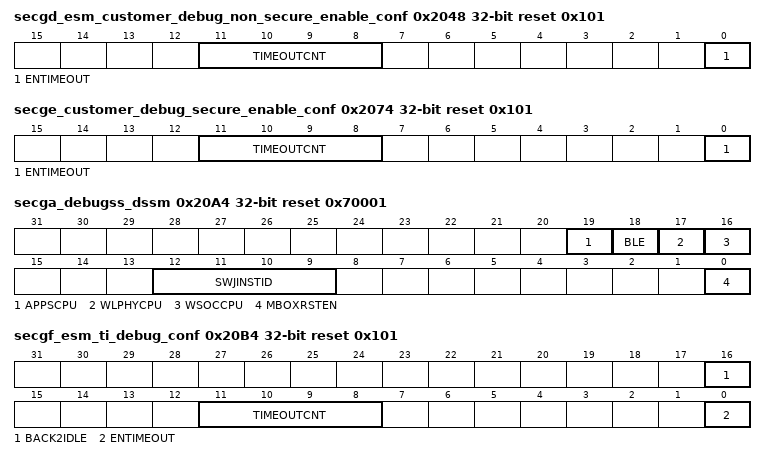
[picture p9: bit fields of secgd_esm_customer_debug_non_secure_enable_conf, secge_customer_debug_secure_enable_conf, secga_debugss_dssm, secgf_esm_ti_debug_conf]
0x2048 secgd_esm_customer_debug_non_secure_enable_conf reset 0x101 — ESM1 Configuration- Customer Debug M33 Non Secure Enable Sequence Monitor. Enable timeout mechanism and timeout counter value.
  [11:8] TIMEOUTCNT rw — This field sets the timeout value. time resolution equals to 16us. while: value 0 representing 16us value 1 - 2*16us value 2 - 3*16us and so on. value 15 is not supported.
  [0] ENTIMEOUT rw — This field enables timeout mechanism for ESM.
0x204C customer_debug_non_secure_enable_en1 — ESM1 Enable Number 1.
  [0] EN1 wo — This field is the 1st enable for the ESM. Type: Write-Clear
0x2050 customer_debug_non_secure_enable_en2 — ESM1 Enable Number 2.
  [0] EN2 wo — This field is the 2nd enable for the ESM. Type: Write-Clear
0x2054 customer_debug_non_secure_enable_en3 — ESM1 Enable Number 3.
  [0] EN3 wo — This field is the 3rd enable for the ESM. Type: Write-Clear
0x2058 customer_debug_non_secure_enable_en4 — ESM1 Enable Number 4.
  [0] EN4 wo — This field is the 4th enable for the ESM. Type: Write-Clear
0x205C customer_debug_non_secure_enable_en5 — ESM1 Enable Number 5.
  [0] EN5 wo — This field is the 5th enable for the ESM. Type: Write-Clear
0x2060 customer_debug_secure_enable_en1 — ESM2 Enable Number 1.
  fields as customer_debug_non_secure_enable_en1
0x2064 customer_debug_secure_enable_en2 — ESM2 Enable Number 2.
  fields as customer_debug_non_secure_enable_en2
0x2068 customer_debug_secure_enable_en3 — ESM2 Enable Number 3.
  fields as customer_debug_non_secure_enable_en3
0x206C customer_debug_secure_enable_en4 — ESM2 Enable Number 4.
  fields as customer_debug_non_secure_enable_en4
0x2070 customer_debug_secure_enable_en5 — ESM2 Enable Number 5.
  fields as customer_debug_non_secure_enable_en5
0x2074 secge_customer_debug_secure_enable_conf reset 0x101 — ESM2 Configuration- Customer Debug M33 Secure Enable Sequence Monitor. Enable timeout mechanism and timeout counter value.
  fields as secgd_esm_customer_debug_non_secure_enable_conf
0x20A4 secga_debugss_dssm reset 0x70001 — This register allow indication of debug port is present: ble, wlphy, wsoccpu, app cpu
  [19] APPSCPU rw — HOST M33 MCU , debug port present (enable), locked on boot done applicable only for MDB
  [18] BLE rw — BLE MCU , debug port present (enable), locked on boot done
  [17] WLPHYCPU rw — WLPHY MCU , debug port present (enable), locked on boot done
  [16] WSOCCPU rw — WSOC MCU , debug port present (enable), locked on boot done
  [12:9] SWJINSTID rw — Single wire Jtag, these field set the instance ID for multi probe SWJDP configuration, going to debugss and locked on boot done
  [0] MBOXRSTEN rw — If this signal is set, debug request command sent to DSSM TX DAT register shall assert "Mailbox_reset_req" signal above, otherwise the debug request command is ignored.
0x20B4 secgf_esm_ti_debug_conf reset 0x101 — ESM3 Configuration- TI Debug Enable Sequence Monitor. Enable timeout mechanism and timeout counter value.
  [16] BACK2IDLE rw — 1 - Allow ESM3 to be restarted (IDLE) when entering Elevated mode 0 - Keep ESM3 state (not restarted) when entering Elevated mode
  [11:8] TIMEOUTCNT rw — This field sets the timeout value. time resolution equals to 16us. while: value 0 representing 16us value 1 - 2*16us value 2 - 3*16us and so on. value 15 is not supported.
  [0] ENTIMEOUT rw — This field enables timeout mechanism for ESM.
0x20B8 ti_debug_en1 — ESM3 Enable Number 1.
  fields as customer_debug_non_secure_enable_en1
0x20BC ti_debug_en2 — ESM3 Enable Number 2.
  fields as customer_debug_non_secure_enable_en2
0x20C0 ti_debug_en3 — ESM3 Enable Number 3.
  fields as customer_debug_non_secure_enable_en3
0x20C4 ti_debug_en4 — ESM3 Enable Number 4.
  fields as customer_debug_non_secure_enable_en4
0x20C8 ti_debug_en5 — ESM3 Enable Number 5.
  fields as customer_debug_non_secure_enable_en5
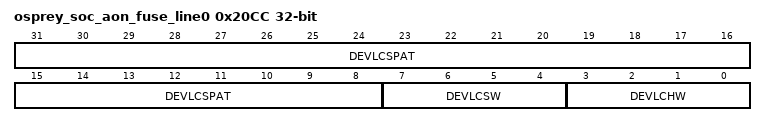
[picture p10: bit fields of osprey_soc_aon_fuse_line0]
0x20CC osprey_soc_aon_fuse_line0 ro — Fuse Line 0. Actual fuse line is 32
  [31:8] DEVLCSPAT — Device Life Cycle Operational (Strong Pattern) 24'hca5b3a Device Life Cycle AT TEST Privilege (Strong Pattern) Allows unhide the assets in device AT TEST for TI debug/development. 24'h484a28 (This number allows moving to operational assuming no HW CRC is disabled)
  [7:4] DEVLCSW — Device Life Cycle (SW Managed)
  [3:0] DEVLCHW — Device Life Cycle (HW Managed) - Programmed on Package 0 - 1st Birthday 1 - ATTEST (For Development) 3 - Operational (For Customer) 7 - Reserved
